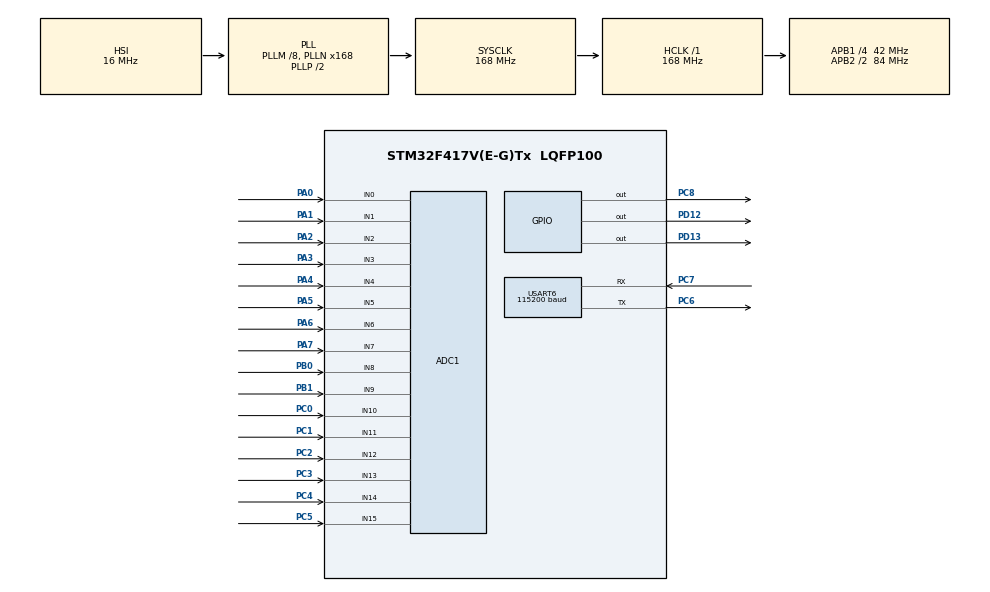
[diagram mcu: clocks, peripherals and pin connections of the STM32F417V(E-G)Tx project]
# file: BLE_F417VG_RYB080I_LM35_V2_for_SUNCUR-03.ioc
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Mcu.Family=STM32F4
ADC1.Rank-14\#ChannelRegularConversion=15
RCC.CortexFreq_Value=168000000
ADC1.ContinuousConvMode=DISABLE
SH.ADCx_IN2.0=ADC1_IN2,IN2
ADC1.SamplingTime-6\#ChannelRegularConversion=ADC_SAMPLETIME_3CYCLES
ADC1.SamplingTime-12\#ChannelRegularConversion=ADC_SAMPLETIME_3CYCLES
ADC1.Channel-14\#ChannelRegularConversion=ADC_CHANNEL_8
ADC1.Channel-8\#ChannelRegularConversion=ADC_CHANNEL_4
RCC.SYSCLKSource=RCC_SYSCLKSOURCE_PLLCLK
ProjectManager.StackSize=0x400
PD13.Signal=GPIO_Output
ADC1.Channel-5\#ChannelRegularConversion=ADC_CHANNEL_1
ADC1.Rank-11\#ChannelRegularConversion=12
ADC1.Channel-3\#ChannelRegularConversion=ADC_CHANNEL_13
RCC.HCLKFreq_Value=168000000
SH.ADCx_IN3.0=ADC1_IN3,IN3
RCC.APB2TimFreq_Value=168000000
ADC1.Channel-2\#ChannelRegularConversion=ADC_CHANNEL_12
PC7.Signal=USART6_RX
PC3.Signal=ADCx_IN13
RCC.AHBFreq_Value=168000000
ADC1.Channel-0\#ChannelRegularConversion=ADC_CHANNEL_10
RCC.HSE_VALUE=25000000
ADC1.ScanConvMode=ENABLE
SH.ADCx_IN15.0=ADC1_IN15,IN15
ADC1.SamplingTime-4\#ChannelRegularConversion=ADC_SAMPLETIME_3CYCLES
ADC1.Channel-6\#ChannelRegularConversion=ADC_CHANNEL_2
ADC1.Rank-2\#ChannelRegularConversion=3
NVIC.TIM2_IRQn=true\:0\:0\:false\:false\:true\:true\:true
SH.ADCx_IN8.0=ADC1_IN8,IN8
SH.ADCx_IN0.0=ADC1_IN0,IN0
ADC1.Channel-15\#ChannelRegularConversion=ADC_CHANNEL_9
ADC1.SamplingTime-0\#ChannelRegularConversion=ADC_SAMPLETIME_3CYCLES
ADC1.Rank-15\#ChannelRegularConversion=16
Mcu.Package=LQFP100
ADC1.SamplingTime-11\#ChannelRegularConversion=ADC_SAMPLETIME_3CYCLES
TIM2.Prescaler=8400-1
PA6.Signal=ADCx_IN6
PB1.Signal=ADCx_IN9
SH.ADCx_IN14.0=ADC1_IN14,IN14
USART6.VirtualMode=VM_ASYNC
PD12.Signal=GPIO_Output
ADC1.SamplingTime-13\#ChannelRegularConversion=ADC_SAMPLETIME_3CYCLES
ADC1.Channel-11\#ChannelRegularConversion=ADC_CHANNEL_7
USART6.BaudRate=115200
SH.ADCx_IN9.0=ADC1_IN9,IN9
RCC.APB2CLKDivider=RCC_HCLK_DIV2
SH.ADCx_IN1.0=ADC1_IN1,IN1
ADC1.SamplingTime-15\#ChannelRegularConversion=ADC_SAMPLETIME_3CYCLES
RCC.APB1TimFreq_Value=84000000
PC5.Signal=ADCx_IN15
ADC1.Rank-6\#ChannelRegularConversion=7
ADC1.SamplingTime-8\#ChannelRegularConversion=ADC_SAMPLETIME_3CYCLES
ADC1.Rank-4\#ChannelRegularConversion=5
PA3.Signal=ADCx_IN3
ADC1.Channel-10\#ChannelRegularConversion=ADC_CHANNEL_6
SH.ADCx_IN13.0=ADC1_IN13,IN13
ADC1.Rank-0\#ChannelRegularConversion=1
ADC1.Channel-4\#ChannelRegularConversion=ADC_CHANNEL_0
ADC1.Rank-10\#ChannelRegularConversion=11
SH.ADCx_IN6.0=ADC1_IN6,IN6
ADC1.Rank-8\#ChannelRegularConversion=9
PC8.Signal=GPIO_Output
PC4.Signal=ADCx_IN14
PC2.Signal=ADCx_IN12
PC6.Signal=USART6_TX
ADC1.DiscontinuousConvMode=ENABLE
ADC1.Channel-13\#ChannelRegularConversion=ADC_CHANNEL_15
PC0.Signal=ADCx_IN10
RCC.APB1CLKDivider=RCC_HCLK_DIV4
ADC1.SamplingTime-2\#ChannelRegularConversion=ADC_SAMPLETIME_3CYCLES
PA0-WKUP.Signal=ADCx_IN0
ADC1.Channel-7\#ChannelRegularConversion=ADC_CHANNEL_3
ADC1.Rank-13\#ChannelRegularConversion=14
SH.ADCx_IN12.0=ADC1_IN12,IN12
ProjectManager.TargetToolchain=STM32CubeIDE
SH.ADCx_IN7.0=ADC1_IN7,IN7
PC6.Mode=Asynchronous
ADC1.Channel-1\#ChannelRegularConversion=ADC_CHANNEL_11
RCC.LSE_VALUE=32768
PA1.Signal=ADCx_IN1
PA5.Signal=ADCx_IN5
board=custom
ADC1.Rank-12\#ChannelRegularConversion=13
RCC.VCOOutputFreq_Value=336000000
ADC1.SamplingTime-14\#ChannelRegularConversion=ADC_SAMPLETIME_3CYCLES
ADC1.Channel-12\#ChannelRegularConversion=ADC_CHANNEL_14
RCC.APB2Freq_Value=84000000
SH.ADCx_IN11.0=ADC1_IN11,IN11
VP_TIM2_VS_ClockSourceINT.Mode=Internal
SH.ADCx_IN4.0=ADC1_IN4,IN4
ADC1.SamplingTime-10\#ChannelRegularConversion=ADC_SAMPLETIME_3CYCLES
TIM2.Period=10000-1
ADC1.Rank-9\#ChannelRegularConversion=10
ADC1.NbrOfConversion=16
Mcu.Name=STM32F417V(E-G)Tx
PA2.Signal=ADCx_IN2
ADC1.Channel-9\#ChannelRegularConversion=ADC_CHANNEL_5
RCC.48MHZClocksFreq_Value=84000000
PA4.Signal=ADCx_IN4
ADC1.SamplingTime-1\#ChannelRegularConversion=ADC_SAMPLETIME_3CYCLES
RCC.SYSCLKFreq_VALUE=168000000
ADC1.master=1
ADC1.Rank-3\#ChannelRegularConversion=4
ADC1.SamplingTime-3\#ChannelRegularConversion=ADC_SAMPLETIME_3CYCLES
ADC1.Rank-1\#ChannelRegularConversion=2
SH.ADCx_IN10.0=ADC1_IN10,IN10
ProjectManager.HeapSize=0x200
ADC1.SamplingTime-5\#ChannelRegularConversion=ADC_SAMPLETIME_3CYCLES
RCC.HSI_VALUE=16000000
SH.ADCx_IN5.0=ADC1_IN5,IN5
ADC1.Rank-7\#ChannelRegularConversion=8
NVIC.PriorityGroup=NVIC_PRIORITYGROUP_4
ADC1.NbrOfConversionFlag=1
RCC.PLLM=8
RCC.PLLN=168
ADC1.SamplingTime-9\#ChannelRegularConversion=ADC_SAMPLETIME_3CYCLES
ADC1.SamplingTime-7\#ChannelRegularConversion=ADC_SAMPLETIME_3CYCLES
PC7.Mode=Asynchronous
RCC.APB1Freq_Value=42000000
PB0.Signal=ADCx_IN8
ADC1.Rank-5\#ChannelRegularConversion=6
PC1.Signal=ADCx_IN11
PA7.Signal=ADCx_IN7

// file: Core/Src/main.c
/* USER CODE BEGIN Header */
/**
  ******************************************************************************
  * @file           : main.c
  * @brief          : Main program body
  ******************************************************************************
  * @attention
  *
  * <h2><center>&copy; Copyright (c) 2019 STMicroelectronics.
  * All rights reserved.</center></h2>
  *
  * This software component is licensed by ST under BSD 3-Clause license,
  * the "License"; You may not use this file except in compliance with the
  * License. You may obtain a copy of the License at:
  *                        opensource.org/licenses/BSD-3-Clause
  *
  ******************************************************************************
  *Program for PCB: BLE_F417_ADC_V3
  ******************************************************************************
  */
/* USER CODE END Header */

#include "main.h"

/* USER CODE BEGIN PTD */
USART_BLE USARTBLE;	//TODO:--wayne20191211
/* USER CODE END PTD */

ADC_HandleTypeDef hadc1;

TIM_HandleTypeDef htim2;

UART_HandleTypeDef huart6;

void SystemClock_Config(void);
static void MX_GPIO_Init(void);
static void MX_ADC1_Init(void);
static void MX_TIM2_Init(void);
static void MX_USART6_UART_Init(void);

int main(void)
{

  /* MCU Configuration--------------------------------------------------------*/

  /* Reset of all peripherals, Initializes the Flash interface and the Systick. */
  HAL_Init();

  /* Configure the system clock */
  SystemClock_Config();

  /* Initialize all configured peripherals */
  MX_GPIO_Init();
  MX_ADC1_Init();
  MX_TIM2_Init();
  MX_USART6_UART_Init();
  /* USER CODE BEGIN 2 */
  HAL_TIM_Base_Start_IT(&htim2);//UART TIM
  RYB080E_Init();
  /* USER CODE END 2 */

  /* Infinite loop */
  while (1)
  {

    /* USER CODE BEGIN 3 */
	  ADC1_Conv(&hadc1);
	  BLE_USART(&huart6);
  }
  /* USER CODE END 3 */
}

void SystemClock_Config(void)
{
  RCC_OscInitTypeDef RCC_OscInitStruct = {0};
  RCC_ClkInitTypeDef RCC_ClkInitStruct = {0};

  /** Configure the main internal regulator output voltage
  */
  __HAL_RCC_PWR_CLK_ENABLE();
  __HAL_PWR_VOLTAGESCALING_CONFIG(PWR_REGULATOR_VOLTAGE_SCALE1);
  /** Initializes the CPU, AHB and APB busses clocks
  */
  RCC_OscInitStruct.OscillatorType = RCC_OSCILLATORTYPE_HSI;
  RCC_OscInitStruct.HSIState = RCC_HSI_ON;
  RCC_OscInitStruct.HSICalibrationValue = RCC_HSICALIBRATION_DEFAULT;
  RCC_OscInitStruct.PLL.PLLState = RCC_PLL_ON;
  RCC_OscInitStruct.PLL.PLLSource = RCC_PLLSOURCE_HSI;
  RCC_OscInitStruct.PLL.PLLM = 8;
  RCC_OscInitStruct.PLL.PLLN = 168;
  RCC_OscInitStruct.PLL.PLLP = RCC_PLLP_DIV2;
  RCC_OscInitStruct.PLL.PLLQ = 4;
  if (HAL_RCC_OscConfig(&RCC_OscInitStruct) != HAL_OK)
  {
    Error_Handler();
  }
  /** Initializes the CPU, AHB and APB busses clocks
  */
  RCC_ClkInitStruct.ClockType = RCC_CLOCKTYPE_HCLK|RCC_CLOCKTYPE_SYSCLK
                              |RCC_CLOCKTYPE_PCLK1|RCC_CLOCKTYPE_PCLK2;
  RCC_ClkInitStruct.SYSCLKSource = RCC_SYSCLKSOURCE_PLLCLK;
  RCC_ClkInitStruct.AHBCLKDivider = RCC_SYSCLK_DIV1;
  RCC_ClkInitStruct.APB1CLKDivider = RCC_HCLK_DIV4;
  RCC_ClkInitStruct.APB2CLKDivider = RCC_HCLK_DIV2;

  if (HAL_RCC_ClockConfig(&RCC_ClkInitStruct, FLASH_LATENCY_5) != HAL_OK)
  {
    Error_Handler();
  }
}

static void MX_ADC1_Init(void)
{

  ADC_ChannelConfTypeDef sConfig = {0};

  /** Configure the global features of the ADC (Clock, Resolution, Data Alignment and number of conversion)
  */
  hadc1.Instance = ADC1;
  hadc1.Init.ClockPrescaler = ADC_CLOCK_SYNC_PCLK_DIV4;
  hadc1.Init.Resolution = ADC_RESOLUTION_12B;
  hadc1.Init.ScanConvMode = ENABLE;
  hadc1.Init.ContinuousConvMode = DISABLE;
  hadc1.Init.DiscontinuousConvMode = ENABLE;
  hadc1.Init.NbrOfDiscConversion = 1;
  hadc1.Init.ExternalTrigConvEdge = ADC_EXTERNALTRIGCONVEDGE_NONE;
  hadc1.Init.ExternalTrigConv = ADC_SOFTWARE_START;
  hadc1.Init.DataAlign = ADC_DATAALIGN_RIGHT;
  hadc1.Init.NbrOfConversion = 16;
  hadc1.Init.DMAContinuousRequests = DISABLE;
  hadc1.Init.EOCSelection = ADC_EOC_SINGLE_CONV;
  if (HAL_ADC_Init(&hadc1) != HAL_OK)
  {
    Error_Handler();
  }
  /** Configure for the selected ADC regular channel its corresponding rank in the sequencer and its sample time.
  */
  sConfig.Channel = ADC_CHANNEL_10;
  sConfig.Rank = 1;
  sConfig.SamplingTime = ADC_SAMPLETIME_3CYCLES;
  if (HAL_ADC_ConfigChannel(&hadc1, &sConfig) != HAL_OK)
  {
    Error_Handler();
  }
  /** Configure for the selected ADC regular channel its corresponding rank in the sequencer and its sample time.
  */
  sConfig.Channel = ADC_CHANNEL_11;
  sConfig.Rank = 2;
  if (HAL_ADC_ConfigChannel(&hadc1, &sConfig) != HAL_OK)
  {
    Error_Handler();
  }
  /** Configure for the selected ADC regular channel its corresponding rank in the sequencer and its sample time.
  */
  sConfig.Channel = ADC_CHANNEL_12;
  sConfig.Rank = 3;
  if (HAL_ADC_ConfigChannel(&hadc1, &sConfig) != HAL_OK)
  {
    Error_Handler();
  }
  /** Configure for the selected ADC regular channel its corresponding rank in the sequencer and its sample time.
  */
  sConfig.Channel = ADC_CHANNEL_13;
  sConfig.Rank = 4;
  if (HAL_ADC_ConfigChannel(&hadc1, &sConfig) != HAL_OK)
  {
    Error_Handler();
  }
  /** Configure for the selected ADC regular channel its corresponding rank in the sequencer and its sample time.
  */
  sConfig.Channel = ADC_CHANNEL_0;
  sConfig.Rank = 5;
  if (HAL_ADC_ConfigChannel(&hadc1, &sConfig) != HAL_OK)
  {
    Error_Handler();
  }
  /** Configure for the selected ADC regular channel its corresponding rank in the sequencer and its sample time.
  */
  sConfig.Channel = ADC_CHANNEL_1;
  sConfig.Rank = 6;
  if (HAL_ADC_ConfigChannel(&hadc1, &sConfig) != HAL_OK)
  {
    Error_Handler();
  }
  /** Configure for the selected ADC regular channel its corresponding rank in the sequencer and its sample time.
  */
  sConfig.Channel = ADC_CHANNEL_2;
  sConfig.Rank = 7;
  if (HAL_ADC_ConfigChannel(&hadc1, &sConfig) != HAL_OK)
  {
    Error_Handler();
  }
  /** Configure for the selected ADC regular channel its corresponding rank in the sequencer and its sample time.
  */
  sConfig.Channel = ADC_CHANNEL_3;
  sConfig.Rank = 8;
  if (HAL_ADC_ConfigChannel(&hadc1, &sConfig) != HAL_OK)
  {
    Error_Handler();
  }
  /** Configure for the selected ADC regular channel its corresponding rank in the sequencer and its sample time.
  */
  sConfig.Channel = ADC_CHANNEL_4;
  sConfig.Rank = 9;
  if (HAL_ADC_ConfigChannel(&hadc1, &sConfig) != HAL_OK)
  {
    Error_Handler();
  }
  /** Configure for the selected ADC regular channel its corresponding rank in the sequencer and its sample time.
  */
  sConfig.Channel = ADC_CHANNEL_5;
  sConfig.Rank = 10;
  if (HAL_ADC_ConfigChannel(&hadc1, &sConfig) != HAL_OK)
  {
    Error_Handler();
  }
  /** Configure for the selected ADC regular channel its corresponding rank in the sequencer and its sample time.
  */
  sConfig.Channel = ADC_CHANNEL_6;
  sConfig.Rank = 11;
  if (HAL_ADC_ConfigChannel(&hadc1, &sConfig) != HAL_OK)
  {
    Error_Handler();
  }
  /** Configure for the selected ADC regular channel its corresponding rank in the sequencer and its sample time.
  */
  sConfig.Channel = ADC_CHANNEL_7;
  sConfig.Rank = 12;
  if (HAL_ADC_ConfigChannel(&hadc1, &sConfig) != HAL_OK)
  {
    Error_Handler();
  }
  /** Configure for the selected ADC regular channel its corresponding rank in the sequencer and its sample time.
  */
  sConfig.Channel = ADC_CHANNEL_14;
  sConfig.Rank = 13;
  if (HAL_ADC_ConfigChannel(&hadc1, &sConfig) != HAL_OK)
  {
    Error_Handler();
  }
  /** Configure for the selected ADC regular channel its corresponding rank in the sequencer and its sample time.
  */
  sConfig.Channel = ADC_CHANNEL_15;
  sConfig.Rank = 14;
  if (HAL_ADC_ConfigChannel(&hadc1, &sConfig) != HAL_OK)
  {
    Error_Handler();
  }
  /** Configure for the selected ADC regular channel its corresponding rank in the sequencer and its sample time.
  */
  sConfig.Channel = ADC_CHANNEL_8;
  sConfig.Rank = 15;
  if (HAL_ADC_ConfigChannel(&hadc1, &sConfig) != HAL_OK)
  {
    Error_Handler();
  }
  /** Configure for the selected ADC regular channel its corresponding rank in the sequencer and its sample time.
  */
  sConfig.Channel = ADC_CHANNEL_9;
  sConfig.Rank = 16;
  if (HAL_ADC_ConfigChannel(&hadc1, &sConfig) != HAL_OK)
  {
    Error_Handler();
  }

}

static void MX_TIM2_Init(void)
{

  TIM_ClockConfigTypeDef sClockSourceConfig = {0};
  TIM_MasterConfigTypeDef sMasterConfig = {0};

  htim2.Instance = TIM2;
  htim2.Init.Prescaler = 8400-1;
  htim2.Init.CounterMode = TIM_COUNTERMODE_UP;
  htim2.Init.Period = 10000-1;
  htim2.Init.ClockDivision = TIM_CLOCKDIVISION_DIV1;
  htim2.Init.AutoReloadPreload = TIM_AUTORELOAD_PRELOAD_DISABLE;
  if (HAL_TIM_Base_Init(&htim2) != HAL_OK)
  {
    Error_Handler();
  }
  sClockSourceConfig.ClockSource = TIM_CLOCKSOURCE_INTERNAL;
  if (HAL_TIM_ConfigClockSource(&htim2, &sClockSourceConfig) != HAL_OK)
  {
    Error_Handler();
  }
  sMasterConfig.MasterOutputTrigger = TIM_TRGO_RESET;
  sMasterConfig.MasterSlaveMode = TIM_MASTERSLAVEMODE_DISABLE;
  if (HAL_TIMEx_MasterConfigSynchronization(&htim2, &sMasterConfig) != HAL_OK)
  {
    Error_Handler();
  }

}

static void MX_USART6_UART_Init(void)
{

  huart6.Instance = USART6;
  huart6.Init.BaudRate = 115200;
  huart6.Init.WordLength = UART_WORDLENGTH_8B;
  huart6.Init.StopBits = UART_STOPBITS_1;
  huart6.Init.Parity = UART_PARITY_NONE;
  huart6.Init.Mode = UART_MODE_TX_RX;
  huart6.Init.HwFlowCtl = UART_HWCONTROL_NONE;
  huart6.Init.OverSampling = UART_OVERSAMPLING_16;
  if (HAL_UART_Init(&huart6) != HAL_OK)
  {
    Error_Handler();
  }

}

static void MX_GPIO_Init(void)
{
  GPIO_InitTypeDef GPIO_InitStruct = {0};

  /* GPIO Ports Clock Enable */
  __HAL_RCC_GPIOC_CLK_ENABLE();
  __HAL_RCC_GPIOA_CLK_ENABLE();
  __HAL_RCC_GPIOB_CLK_ENABLE();
  __HAL_RCC_GPIOD_CLK_ENABLE();

  /*Configure GPIO pin Output Level */
  HAL_GPIO_WritePin(GPIOD, GPIO_PIN_12|GPIO_PIN_13, GPIO_PIN_RESET);

  /*Configure GPIO pin Output Level */
  HAL_GPIO_WritePin(GPIOC, GPIO_PIN_8, GPIO_PIN_RESET);

  /*Configure GPIO pins : PD12 PD13 */
  GPIO_InitStruct.Pin = GPIO_PIN_12|GPIO_PIN_13;
  GPIO_InitStruct.Mode = GPIO_MODE_OUTPUT_PP;
  GPIO_InitStruct.Pull = GPIO_NOPULL;
  GPIO_InitStruct.Speed = GPIO_SPEED_FREQ_LOW;
  HAL_GPIO_Init(GPIOD, &GPIO_InitStruct);

  /*Configure GPIO pin : PC8 */
  GPIO_InitStruct.Pin = GPIO_PIN_8;
  GPIO_InitStruct.Mode = GPIO_MODE_OUTPUT_PP;
  GPIO_InitStruct.Pull = GPIO_NOPULL;
  GPIO_InitStruct.Speed = GPIO_SPEED_FREQ_LOW;
  HAL_GPIO_Init(GPIOC, &GPIO_InitStruct);

}

/* USER CODE BEGIN 4 */
void HAL_TIM_PeriodElapsedCallback(TIM_HandleTypeDef *htim)//TODO:--wayne20191211
{
	 if (htim->Instance == htim2.Instance)
	 {
		 USARTBLE.SecCount++;
		 if(USARTBLE.SecCount==1)
		 {
			 USARTBLE.sendflag = 1;
			 USARTBLE.SecCount=0;
		 }
	 }
}

/* USER CODE END 4 */

void Error_Handler(void)
{
}

/************************ (C) COPYRIGHT STMicroelectronics *****END OF FILE****/
